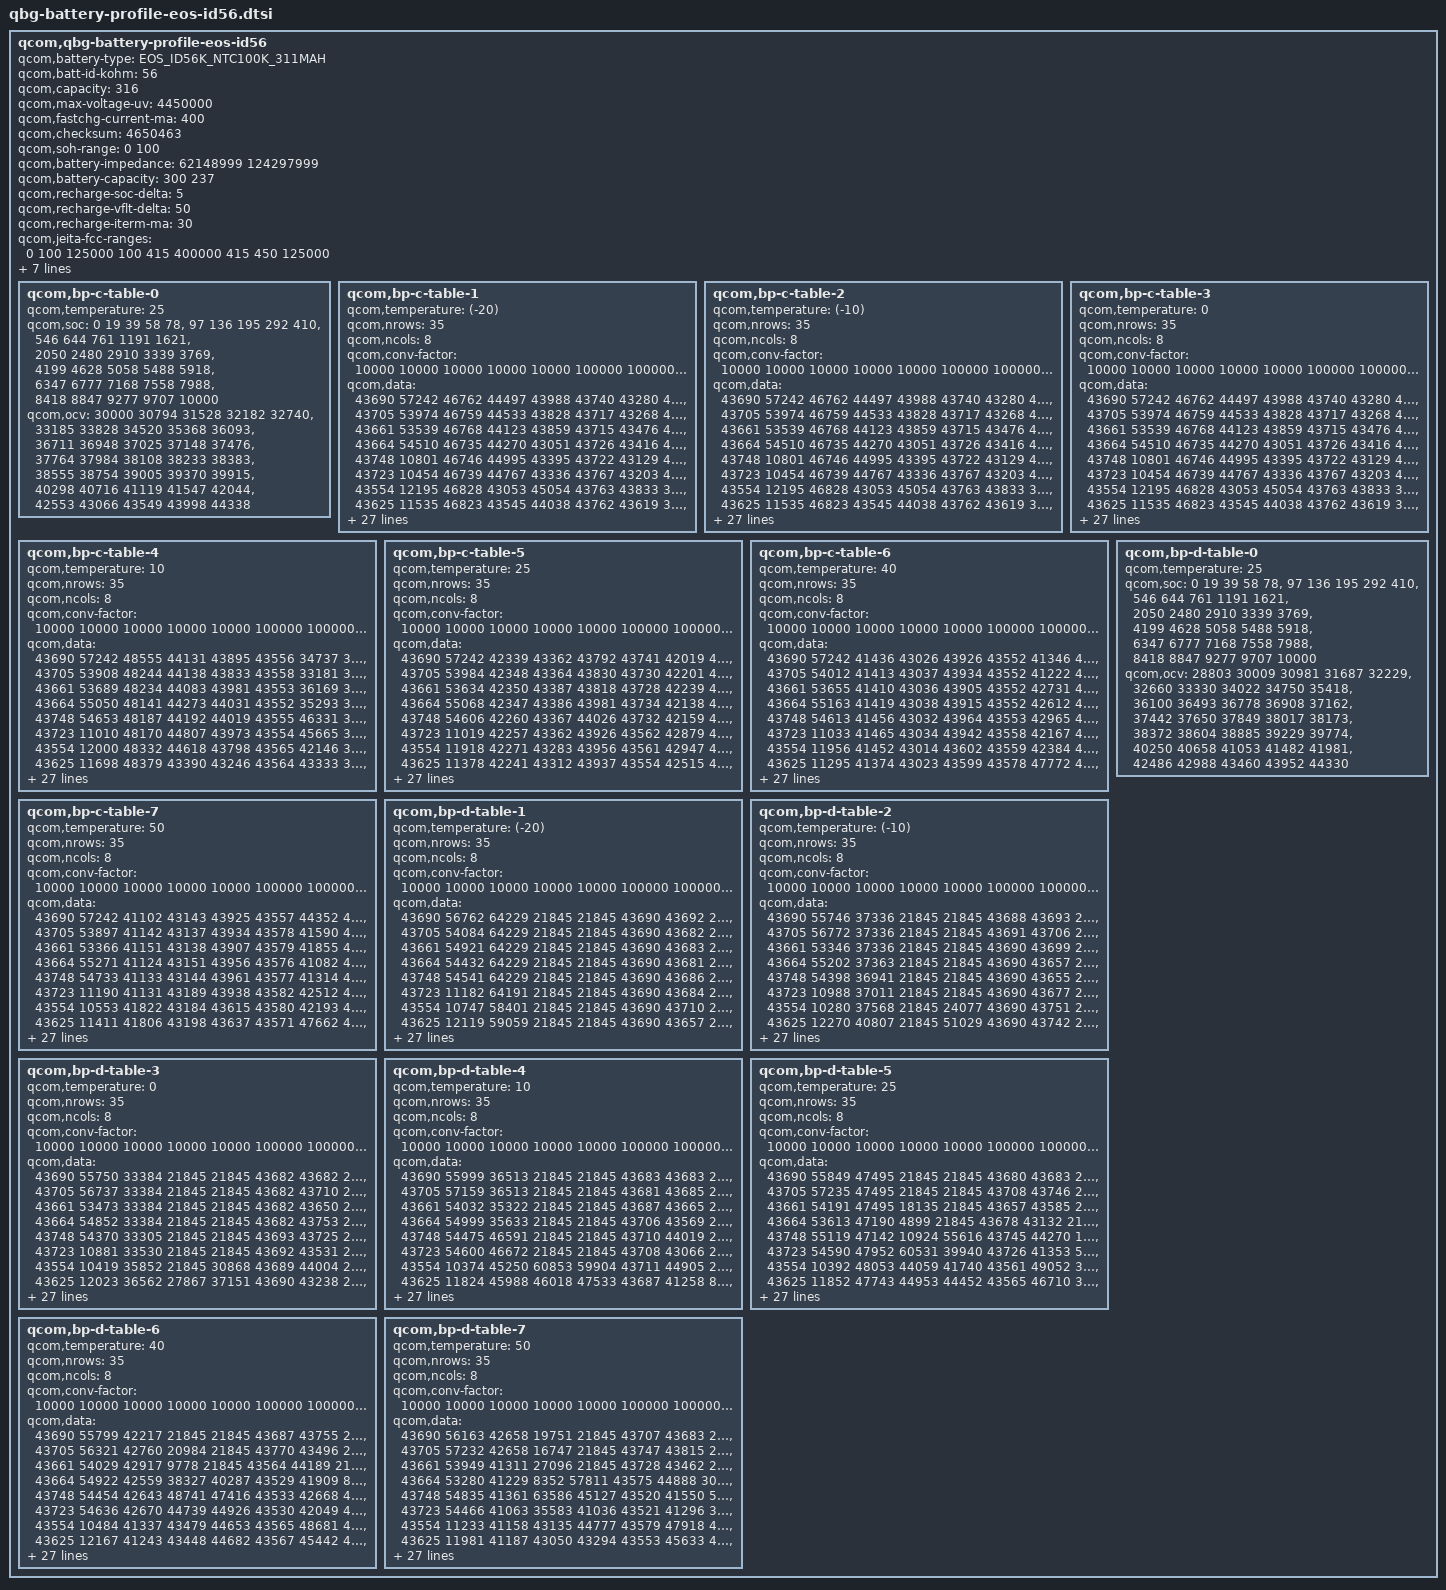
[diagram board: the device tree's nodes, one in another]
// SPDX-License-Identifier: GPL-2.0

/*QBG Profiling Rev. 2.7*/

qcom,qbg-battery-profile-eos-id56 {
	qcom,battery-type = "EOS_ID56K_NTC100K_311MAH";
	qcom,batt-id-kohm = <56>;
	qcom,capacity = <316>;
	qcom,max-voltage-uv = <4450000>;
	qcom,fastchg-current-ma = <400>;
	qcom,checksum = <4650463>; /*@5, 0.005V, 4% */
	qcom,soh-range = <0 100>;
	/*Nominal_Impedance in 10nohm @ SOC 50% 25C* 0:fresh cell, 1: aged cell*/
	qcom,battery-impedance = <62148999 124297999>;
	/*Nominal_Capacity in mAh. 0: fresh cell, 1:aged cell*/
	qcom,battery-capacity = <300 237>;
	/*SOC delta (in percent) dropped from EOC SOC to enable recharge*/
	qcom,recharge-soc-delta =<5>;
	/*vfloat delta (in mV) dropped from regular vfloat in recharge*/
	qcom,recharge-vflt-delta =<50>;
	/*termination current (in mA) in recharge*/
	qcom,recharge-iterm-ma = <30>;
	qcom,jeita-fcc-ranges = <0  100 125000
				100 415 400000
				415 450 125000>;

	qcom,jeita-fv-ranges = <0   100 4450000
				100 415 4450000
				415 450 4450000>;

	/* COOL = 10 DegC, WARM = 41 DegC */
	qcom,jeita-soft-thresholds = <0x2b8a 0x14de>;
	/* COLD = 0 DegC, HOT = 45 DegC */
	qcom,jeita-hard-thresholds = <0x3257 0x128c>;
	/* COOL = 12 DegC, WARM = 39 DegC*/
	qcom,jeita-soft-hys-thresholds = <0x2a0b 0x161b>;
	qcom,jeita-soft-fcc-ua = <125000 125000>;
	qcom,jeita-soft-fv-uv = <4450000 4450000>;

	qcom,bp-c-table-0 {
		qcom,temperature = <25>;
		qcom,soc = <    0    19    39    58    78>,
			<   97   136   195   292   410>,
			<  546   644   761  1191  1621>,
			< 2050  2480  2910  3339  3769>,
			< 4199  4628  5058  5488  5918>,
			< 6347  6777  7168  7558  7988>,
			< 8418  8847  9277  9707 10000>;
		qcom,ocv = <30000 30794 31528 32182 32740>,
			<33185 33828 34520 35368 36093>,
			<36711 36948 37025 37148 37476>,
			<37764 37984 38108 38233 38383>,
			<38555 38754 39005 39370 39915>,
			<40298 40716 41119 41547 42044>,
			<42553 43066 43549 43998 44338>;
	};
	qcom,bp-c-table-1 {
		qcom,temperature = <(-20)>;
		qcom,nrows = <35>;
		qcom,ncols = <8>;
		qcom,conv-factor = <10000 10000 10000 10000 10000 100000 100000 10000>;
		qcom,data = <43690 57242 46762 44497 43988 43740 43280 40143>,
			<43705 53974 46759 44533 43828 43717 43268 40787>,
			<43661 53539 46768 44123 43859 43715 43476 40736>,
			<43664 54510 46735 44270 43051 43726 43416 40881>,
			<43748 10801 46746 44995 43395 43722 43129 40454>,
			<43723 10454 46739 44767 43336 43767 43203 40682>,
			<43554 12195 46828 43053 45054 43763 43833 39379>,
			<43625 11535 46823 43545 44038 43762 43619 38950>,
			<43918  8266 46751 43569 44041 43721 43628 39684>,
			<43824  9993 45378 43828 44838 43734 43931 39841>,
			<43144  9562 46768 43232 44560 43564 43824 39638>,
			<43054 14949 45423 43741 44237 43734 43618 39611>,
			<43091 15294 45433 43578 44229 43561 43622 34174>,
			<44557 15155 45383 44062 43805 43530 47894 39497>,
			<44287 14427 45345 41775 43111 43734 48015 39317>,
			<41640 16050 45371 41215 43476 43731 47288 39204>,
			<41754 15965 45491 41037 43381 43740 47628 39382>,
			<41460 16326 45135 41449 44676 43742 47806 39223>,
			<42913 16230 45487 41248 44743 43737 42268 39281>,
			<42003 15516 45454 41331 44547 43739 42241 40595>,
			<47821 15387 45175 42722 44620 43738 47727 40565>,
			<47294 15854 45172 42596 44984 43739 48864 40749>,
			<47464 12956 45123 42897 44594 43736 48453 40927>,
			<49114 13076 45448 42886 44693 43716 42418 40738>,
			<48564 12700 45367 43006 44562 43724 41709 39965>,
			<45665 13858 46817 42210 44835 43723 44302 37748>,
			<45267 13497 47026 42485 44829 43767 41661 38461>,
			<46762 13624 46969 42272 44083 43760 44813 38003>,
			<46892  2993 46118 47788 44415 43763 44598 59558>,
			<46494  2165 46512 47641 41832 43763 43341 60636>,
			<35400  3602 46354 48050 42498 43761 43496 57677>,
			<34853  3085 35538 48106 48001 43767 43060 63930>,
			<36503   562 35348 48055 45822 43765 43144 63060>,
			<36673   193 35396 47815 36731 43720 43899 51052>,
			<36282   284 35769 42580 34842 43763 43820 50040>;
	};
	qcom,bp-c-table-2 {
		qcom,temperature = <(-10)>;
		qcom,nrows = <35>;
		qcom,ncols = <8>;
		qcom,conv-factor = <10000 10000 10000 10000 10000 100000 100000 10000>;
		qcom,data = <43690 57242 46762 44497 43988 43740 43280 40143>,
			<43705 53974 46759 44533 43828 43717 43268 40787>,
			<43661 53539 46768 44123 43859 43715 43476 40736>,
			<43664 54510 46735 44270 43051 43726 43416 40881>,
			<43748 10801 46746 44995 43395 43722 43129 40454>,
			<43723 10454 46739 44767 43336 43767 43203 40682>,
			<43554 12195 46828 43053 45054 43763 43833 39379>,
			<43625 11535 46823 43545 44038 43762 43619 38950>,
			<43918  8266 46751 43569 44041 43721 43628 39684>,
			<43824  9993 45378 43828 44838 43734 43931 39841>,
			<43144  9562 46768 43232 44560 43564 43824 39638>,
			<43054 14949 45423 43741 44237 43734 43618 39611>,
			<43091 15294 45433 43578 44229 43561 43622 34174>,
			<44557 15155 45383 44062 43805 43530 47894 39497>,
			<44287 14427 45345 41775 43111 43734 48015 39317>,
			<41640 16050 45371 41215 43476 43731 47288 39204>,
			<41754 15965 45491 41037 43381 43740 47628 39382>,
			<41460 16326 45135 41449 44676 43742 47806 39223>,
			<42913 16230 45487 41248 44743 43737 42268 39281>,
			<42003 15516 45454 41331 44547 43739 42241 40595>,
			<47821 15387 45175 42722 44620 43738 47727 40565>,
			<47294 15854 45172 42596 44984 43739 48864 40749>,
			<47464 12956 45123 42897 44594 43736 48453 40927>,
			<49114 13076 45448 42886 44693 43716 42418 40738>,
			<48564 12700 45367 43006 44562 43724 41709 39965>,
			<45665 13858 46817 42210 44835 43723 44302 37748>,
			<45267 13497 47026 42485 44829 43767 41661 38461>,
			<46762 13624 46969 42272 44083 43760 44813 38003>,
			<46892  2993 46118 47788 44415 43763 44598 59558>,
			<46494  2165 46512 47641 41832 43763 43341 60636>,
			<35400  3602 46354 48050 42498 43761 43496 57677>,
			<34853  3085 35538 48106 48001 43767 43060 63930>,
			<36503   562 35348 48055 45822 43765 43144 63060>,
			<36673   193 35396 47815 36731 43720 43899 51052>,
			<36282   284 35769 42580 34842 43763 43820 50040>;
	};
	qcom,bp-c-table-3 {
		qcom,temperature = <0>;
		qcom,nrows = <35>;
		qcom,ncols = <8>;
		qcom,conv-factor = <10000 10000 10000 10000 10000 100000 100000 10000>;
		qcom,data = <43690 57242 46762 44497 43988 43740 43280 40143>,
			<43705 53974 46759 44533 43828 43717 43268 40787>,
			<43661 53539 46768 44123 43859 43715 43476 40736>,
			<43664 54510 46735 44270 43051 43726 43416 40881>,
			<43748 10801 46746 44995 43395 43722 43129 40454>,
			<43723 10454 46739 44767 43336 43767 43203 40682>,
			<43554 12195 46828 43053 45054 43763 43833 39379>,
			<43625 11535 46823 43545 44038 43762 43619 38950>,
			<43918  8266 46751 43569 44041 43721 43628 39684>,
			<43824  9993 45378 43828 44838 43734 43931 39841>,
			<43144  9562 46768 43232 44560 43564 43824 39638>,
			<43054 14949 45423 43741 44237 43734 43618 39611>,
			<43091 15294 45433 43578 44229 43561 43622 34174>,
			<44557 15155 45383 44062 43805 43530 47894 39497>,
			<44287 14427 45345 41775 43111 43734 48015 39317>,
			<41640 16050 45371 41215 43476 43731 47288 39204>,
			<41754 15965 45491 41037 43381 43740 47628 39382>,
			<41460 16326 45135 41449 44676 43742 47806 39223>,
			<42913 16230 45487 41248 44743 43737 42268 39281>,
			<42003 15516 45454 41331 44547 43739 42241 40595>,
			<47821 15387 45175 42722 44620 43738 47727 40565>,
			<47294 15854 45172 42596 44984 43739 48864 40749>,
			<47464 12956 45123 42897 44594 43736 48453 40927>,
			<49114 13076 45448 42886 44693 43716 42418 40738>,
			<48564 12700 45367 43006 44562 43724 41709 39965>,
			<45665 13858 46817 42210 44835 43723 44302 37748>,
			<45267 13497 47026 42485 44829 43767 41661 38461>,
			<46762 13624 46969 42272 44083 43760 44813 38003>,
			<46892  2993 46118 47788 44415 43763 44598 59558>,
			<46494  2165 46512 47641 41832 43763 43341 60636>,
			<35400  3602 46354 48050 42498 43761 43496 57677>,
			<34853  3085 35538 48106 48001 43767 43060 63930>,
			<36503   562 35348 48055 45822 43765 43144 63060>,
			<36673   193 35396 47815 36731 43720 43899 51052>,
			<36282   284 35769 42580 34842 43763 43820 50040>;
	};
	qcom,bp-c-table-4 {
		qcom,temperature = <10>;
		qcom,nrows = <35>;
		qcom,ncols = <8>;
		qcom,conv-factor = <10000 10000 10000 10000 10000 100000 100000 10000>;
		qcom,data = <43690 57242 48555 44131 43895 43556 34737 36150>,
			<43705 53908 48244 44138 43833 43558 33181 36230>,
			<43661 53689 48234 44083 43981 43553 36169 35869>,
			<43664 55050 48141 44273 44031 43552 35293 36072>,
			<43748 54653 48187 44192 44019 43555 46331 36708>,
			<43723 11010 48170 44807 43973 43554 45665 36854>,
			<43554 12000 48332 44618 43798 43565 42146 36384>,
			<43625 11698 48379 43390 43246 43564 43333 35121>,
			<43918  8388 48329 43248 43311 43732 43201 34938>,
			<43824 10133 48986 43369 43168 43577 44749 35059>,
			<43144  9481 48299 44675 43984 43575 41476 35699>,
			<43054 14887 48968 43467 43189 43530 44815 35824>,
			<43091 14951 48923 43380 43780 43573 41592 35717>,
			<44557 15353 48952 45018 43786 43577 47648 35065>,
			<44287 14346 49045 44428 43066 43728 42351 35137>,
			<41640 14697 49078 44325 43404 43731 42454 36501>,
			<41754 15885 48754 44382 43497 43730 42458 36531>,
			<41460 16313 48671 41604 43460 43741 42375 36491>,
			<42913 16340 48678 41723 43325 43741 42828 36508>,
			<42003 16214 48847 41672 43376 43740 41294 36555>,
			<47821 15418 48882 41681 44778 43743 41458 36370>,
			<47294 15773 48893 41582 44592 43742 42927 36844>,
			<47464 12967 48888 41859 44574 43737 47978 36611>,
			<49114 13153 48773 41858 43488 43736 47741 36535>,
			<48564 12603 48828 41701 43461 43739 44523 35210>,
			<45665 14247 48779 41502 43461 43717 44329 35130>,
			<45267 13375 48867 41922 43306 43713 44302 36397>,
			<46762  2740 48684 41822 43377 43725 44181 36627>,
			<46892  2845 48767 40975 44568 43726 44950 36200>,
			<46494  2361 49087 41345 44887 43721 44702 33017>,
			<35400  3880 48903 41335 44393 43726 43274 34561>,
			<34853  3543 48302 41310 40973 43727 43103 39803>,
			<36503   960 48362 41319 42439 43712 43200 40247>,
			<36673   406 48382 41076 48533 43718 43869 38148>,
			<36282  1734 48308 41916 46482 43715 43837 60636>;
	};
	qcom,bp-c-table-5 {
		qcom,temperature = <25>;
		qcom,nrows = <35>;
		qcom,ncols = <8>;
		qcom,conv-factor = <10000 10000 10000 10000 10000 100000 100000 10000>;
		qcom,data = <43690 57242 42339 43362 43792 43741 42019 45731>,
			<43705 53984 42348 43364 43830 43730 42201 48509>,
			<43661 53634 42350 43387 43818 43728 42239 48396>,
			<43664 55068 42347 43386 43981 43734 42138 48607>,
			<43748 54606 42260 43367 44026 43732 42159 48620>,
			<43723 11019 42257 43362 43926 43562 42879 48562>,
			<43554 11918 42271 43283 43956 43561 42947 48232>,
			<43625 11378 42241 43312 43937 43554 42515 48371>,
			<43918  8322 42436 43500 43928 43557 44361 48971>,
			<43824  9815 42494 43427 44028 43570 44073 48934>,
			<43144  9677 42396 43117 44021 43572 44081 49025>,
			<43054 15102 42420 43121 43940 43571 41064 48745>,
			<43091 14859 42400 43097 43588 43580 42748 48655>,
			<44557 15286 42051 43477 43848 43578 41777 48988>,
			<44287 14542 41999 44720 43047 43554 41939 48244>,
			<41640 14638 42203 44790 43086 43552 41116 48538>,
			<41754 16074 42219 44553 43008 43555 42569 48546>,
			<41460 15990 42122 44573 43056 43564 42745 48245>,
			<42913 16371 42836 44643 43107 43554 41129 48554>,
			<42003 16197 42868 44740 43305 43564 44264 48618>,
			<47821 15409 42861 44796 44703 43733 44915 48397>,
			<47294 15816 42783 44576 44786 43732 44519 45745>,
			<47464 13047 42763 44933 44681 43564 42852 45801>,
			<49114 13152 42815 44856 43393 43578 48713 48498>,
			<48564 12609 42805 44545 43230 43735 44275 48313>,
			<45665 14272 42965 44641 43009 43734 44951 48330>,
			<45267 13734 42964 44866 43864 43530 42422 48204>,
			<46762  2613 42964 44894 43041 43554 41742 48446>,
			<46892  2273 42795 44194 43414 43743 44556 45823>,
			<46494  3734 42789 44133 43264 43740 44765 45885>,
			<35400  3219 42777 44310 44611 43736 43359 46728>,
			<34853   656 42822 44408 44099 43743 43401 46302>,
			<36503   183 42161 44386 41746 43732 43111 35792>,
			<36673   372 42819 44459 47764 43553 43152 35916>,
			<36282  1944 42901 44602 41313 43729 43859 46396>;
	};
	qcom,bp-c-table-6 {
		qcom,temperature = <40>;
		qcom,nrows = <35>;
		qcom,ncols = <8>;
		qcom,conv-factor = <10000 10000 10000 10000 10000 100000 100000 10000>;
		qcom,data = <43690 57242 41436 43026 43926 43552 41346 47677>,
			<43705 54012 41413 43037 43934 43552 41222 47828>,
			<43661 53655 41410 43036 43905 43552 42731 47823>,
			<43664 55163 41419 43038 43915 43552 42612 47847>,
			<43748 54613 41456 43032 43964 43553 42965 47775>,
			<43723 11033 41465 43034 43942 43558 42167 47799>,
			<43554 11956 41452 43014 43602 43559 42384 42328>,
			<43625 11295 41374 43023 43599 43578 47772 42262>,
			<43918  9048 41393 43070 43632 43581 47809 42449>,
			<43824  9751 41379 43054 43646 43572 47793 42477>,
			<43144  9609 41043 43155 43615 43546 41455 42071>,
			<43054 14987 41050 43875 43584 43548 40961 42200>,
			<43091 15067 41027 43880 43645 43551 42523 42239>,
			<44557 14967 41078 43160 43866 43524 44185 42318>,
			<44287 14519 41065 43248 43208 43522 44910 47835>,
			<41640 14750 40985 43061 43229 43533 44394 47645>,
			<41754 16036 40968 43025 43147 43531 41307 47837>,
			<41460 15873 41018 43046 43870 43574 41550 47800>,
			<42913 16272 41175 43077 43868 43581 41626 47816>,
			<42003 16202 41165 43053 43132 43529 44791 47730>,
			<47821 15414 41214 43148 43388 43529 43301 48098>,
			<47294 15832 41199 43166 44717 43569 44754 47886>,
			<47464 13009 41107 43112 43374 43568 41946 47898>,
			<49114 13136 41114 43430 43060 43574 42892 48040>,
			<48564 12624 41094 43056 43883 43583 44167 42300>,
			<45665 14295 41090 43112 43894 43576 45039 42312>,
			<45267 13705 41097 43432 43150 43553 44587 47837>,
			<46762  2664 41099 43501 43219 43567 43355 48052>,
			<46892  2271 41096 43269 43029 43562 43350 47987>,
			<46494  3789 41090 44701 43073 43732 44775 47156>,
			<35400  3276 41112 44644 43413 43562 44744 47370>,
			<34853   753 41105 44998 44775 43561 44686 49116>,
			<36503   156 41196 45055 44203 43579 43297 48552>,
			<36673   337 41096 44651 41889 43529 43124 45954>,
			<36282  1997 41915 43015 44372 43579 43876 48734>;
	};
	qcom,bp-c-table-7 {
		qcom,temperature = <50>;
		qcom,nrows = <35>;
		qcom,ncols = <8>;
		qcom,conv-factor = <10000 10000 10000 10000 10000 100000 100000 10000>;
		qcom,data = <43690 57242 41102 43143 43925 43557 44352 41987>,
			<43705 53897 41142 43137 43934 43578 41590 42021>,
			<43661 53366 41151 43138 43907 43579 41855 42207>,
			<43664 55271 41124 43151 43956 43576 41082 42230>,
			<43748 54733 41133 43144 43961 43577 41314 42217>,
			<43723 11190 41131 43189 43938 43582 42512 42113>,
			<43554 10553 41822 43184 43615 43580 42193 42837>,
			<43625 11411 41806 43198 43637 43571 47662 42848>,
			<43918  9002 41850 43194 43619 43575 47319 42815>,
			<43824  9978 41832 43172 43540 43529 47479 42948>,
			<43144  9245 41756 43862 43536 43545 47358 42900>,
			<43054  9597 41755 43972 43624 43646 42502 42551>,
			<43091 15006 41734 44002 43627 43643 42741 42718>,
			<44557 14896 41743 43882 43874 43630 44933 42147>,
			<44287 15231 41778 43897 43168 43630 44928 42235>,
			<41640 14405 41764 43177 43188 43624 44116 42022>,
			<41754 14691 41768 43841 43144 43540 41564 42181>,
			<41460 15917 41951 43884 43777 43549 44391 42873>,
			<42913 16265 41923 43151 43839 43535 44381 42164>,
			<42003 16231 41968 43254 43864 43547 44925 42010>,
			<47821 15417 41953 43826 43512 43631 43412 42378>,
			<47294 15838 41877 43983 43369 43543 43460 42433>,
			<47464 12845 41884 43902 43305 43547 44340 42434>,
			<49114 12453 41860 43199 43256 43547 41118 41994>,
			<48564 12625 41859 43899 43991 43546 44877 42971>,
			<45665 14123 41871 43853 43786 43522 44649 42780>,
			<45267 13703 41867 43191 43847 43573 44714 42220>,
			<46762  2657 41908 43043 43198 43583 44785 42063>,
			<46892  2088 41908 43104 43252 43557 44727 42452>,
			<46494  3804 41866 43400 43071 43555 44700 47797>,
			<35400  3290 41870 43292 43106 43564 44575 47705>,
			<34853   712 41868 44681 43456 43555 44581 47285>,
			<36503   156 41865 44773 44607 43530 44788 47614>,
			<36673  1705 41899 43311 44206 43523 43504 47377>,
			<36282  2003 44306 43214 44035 43523 43256 47948>;
	};
	qcom,bp-d-table-0 {
		qcom,temperature = <25>;
		qcom,soc = <    0    19    39    58    78>,
			<   97   136   195   292   410>,
			<  546   644   761  1191  1621>,
			< 2050  2480  2910  3339  3769>,
			< 4199  4628  5058  5488  5918>,
			< 6347  6777  7168  7558  7988>,
			< 8418  8847  9277  9707 10000>;
		qcom,ocv = <28803 30009 30981 31687 32229>,
			<32660 33330 34022 34750 35418>,
			<36100 36493 36778 36908 37162>,
			<37442 37650 37849 38017 38173>,
			<38372 38604 38885 39229 39774>,
			<40250 40658 41053 41482 41981>,
			<42486 42988 43460 43952 44330>;
	};
	qcom,bp-d-table-1 {
		qcom,temperature = <(-20)>;
		qcom,nrows = <35>;
		qcom,ncols = <8>;
		qcom,conv-factor = <10000 10000 10000 10000 10000 100000 100000 10000>;
		qcom,data = <43690 56762 64229 21845 21845 43690 43692 21845>,
			<43705 54084 64229 21845 21845 43690 43682 21845>,
			<43661 54921 64229 21845 21845 43690 43683 21845>,
			<43664 54432 64229 21845 21845 43690 43681 21845>,
			<43748 54541 64229 21845 21845 43690 43686 21845>,
			<43723 11182 64191 21845 21845 43690 43684 21845>,
			<43554 10747 58401 21845 21845 43690 43710 21845>,
			<43625 12119 59059 21845 21845 43690 43657 21845>,
			<43918  9095 57690 21845  1011 43690 43757 21845>,
			<43824  8501 61418 21845 52133 43690 43567 21845>,
			<43144 10224 59889 21845 38468 43690 43961 21845>,
			<43054  9407 60215 21845 34098 43690 43993 21845>,
			<43091  9228 60216 21845 36733 43690 43791 21845>,
			<44557 14978 38905  6142 35113 43691 43124 21845>,
			<44287 15270 36930 10289 35128 43691 43076 21845>,
			<41640 15112 37409 62638 46166 43688 43114 21845>,
			<41754 14571 40937 61404 45758 43688 43403 21845>,
			<41460 14411 40576 40728 47195 43689 43297 20013>,
			<42913 14635 39149 33026 42396 43694 43338 28006>,
			<42003 16002 39477 36562 42711 43695 44680  6398>,
			<47821 15946 34060 46180 40969 43693 44780  3021>,
			<47294 16135 33878 45256 41950 43682 44739 14694>,
			<47464 15392 34731 48215 41583 43680 44792  8914>,
			<49114 15658 34420 49126 44291 43686 44639 54542>,
			<48564 12861 33057 47419 44038 43684 44885 53927>,
			<45665 13149 32818 47546 44901 43706 41541 56100>,
			<45267 12592 32821 47203 44869 43707 41020 56030>,
			<46762 14111 32879 47314 44461 43651 42285 56117>,
			<46892  2766 32789 47282 41533 43742 46668 56931>,
			<46494  2214 32777 47967 41857 43713 47841 57064>,
			<35400  2376 32964 47177 41706 43739 42375 55616>,
			<34853  3253 32790 47425 41601 43712 42283 56997>,
			<36503   753 32847 47390 44394 43760 42908 55801>,
			<36673    85 32880 47975 44226 43756 44988 55811>,
			<36282  2038 33020 42344 44919 43676 43819 50681>;
	};
	qcom,bp-d-table-2 {
		qcom,temperature = <(-10)>;
		qcom,nrows = <35>;
		qcom,ncols = <8>;
		qcom,conv-factor = <10000 10000 10000 10000 10000 100000 100000 10000>;
		qcom,data = <43690 55746 37336 21845 21845 43688 43693 21845>,
			<43705 56772 37336 21845 21845 43691 43706 21845>,
			<43661 53346 37336 21845 21845 43690 43699 21845>,
			<43664 55202 37363 21845 21845 43690 43657 21845>,
			<43748 54398 36941 21845 21845 43690 43655 21845>,
			<43723 10988 37011 21845 21845 43690 43677 21845>,
			<43554 10280 37568 21845 24077 43690 43751 21845>,
			<43625 12270 40807 21845 51029 43690 43742 21845>,
			<43918  8831 39412 21845 34431 43690 43595 21845>,
			<43824  8565 39439 30205 48573 43690 43790 21845>,
			<43144  9357 34763 50774 47815 43691 43084 21845>,
			<43054  9642 34354 58333 42771 43691 43289 21845>,
			<43091  9516 32819 39235 41053 43688 44761 18450>,
			<44557 14871 36143 35742 41049 43694 44955  3135>,
			<44287 15147 36446 45441 41050 43693 44633  8858>,
			<41640 14500 35211 48657 41529 43705 45043 55524>,
			<41754 14368 34953 42309 44820 43770 44147 51309>,
			<41460 14754 35678 42144 44756 43761 44530 61481>,
			<42913 14650 34998 42585 43291 43722 41635 65480>,
			<42003 16015 34986 41297 43494 43727 41608 64257>,
			<47821 15999 35663 41453 43444 43715 41610 58463>,
			<47294 16147 34954 41394 43433 43716 41163 59349>,
			<47464 15453 35702 41227 43094 43743 47228 59276>,
			<49114 13011 35653 41298 43368 43729 48222 59138>,
			<48564 13143 35708 42627 44791 43732 48840 58542>,
			<45665 12592 34991 42506 44667 43563 48727 58564>,
			<45267 14100 34977 42940 44287 43563 48808 58729>,
			<46762 13630 35668 42957 44429 43732 42484 64242>,
			<46892  2629 34988 42852 44247 43731 41379 58656>,
			<46494  2457 35585 42372 44233 43742 42324 64057>,
			<35400  3984 35702 42450 44059 43719 42231 64436>,
			<34853  3485 35702 42297 44048 43712 42606 64452>,
			<36503   950 35658 42479 44184 43727 41062 64070>,
			<36673   499 35676 42127 44591 43767 41657 58434>,
			<36282  2045 34979 42805 43377 43773 44206 59259>;
	};
	qcom,bp-d-table-3 {
		qcom,temperature = <0>;
		qcom,nrows = <35>;
		qcom,ncols = <8>;
		qcom,conv-factor = <10000 10000 10000 10000 10000 100000 100000 10000>;
		qcom,data = <43690 55750 33384 21845 21845 43682 43682 21845>,
			<43705 56737 33384 21845 21845 43682 43710 21845>,
			<43661 53473 33384 21845 21845 43682 43650 21845>,
			<43664 54852 33384 21845 21845 43682 43753 21845>,
			<43748 54370 33305 21845 21845 43693 43725 21845>,
			<43723 10881 33530 21845 21845 43692 43531 21845>,
			<43554 10419 35852 21845 30868 43689 44004 21845>,
			<43625 12023 36562 27867 37151 43690 43238 21845>,
			<43918 11522 34934 62594 47493 43691 43496 21845>,
			<43824  8268 35729 33182 41479 43691 44723 25211>,
			<43144 10093 46395 48380 44810 43689 44824  8514>,
			<43054  9658 46170 48006 44985 43695 44517 57185>,
			<43091  9472 46255 42172 44773 43693 41684 53007>,
			<44557 14893 46706 41056 43468 43709 41906 64315>,
			<44287 15330 45358 41852 43425 43762 41954 58142>,
			<41640 14523 45478 41940 43056 43727 42369 59485>,
			<41754 14766 45558 41942 43127 43739 46704 38269>,
			<41460 14635 45501 41882 43032 43743 45269 38455>,
			<42913 14670 45448 41478 43211 43741 47609 37657>,
			<42003 16069 45457 41507 43245 43731 47955 40281>,
			<47821 16379 45442 41477 43202 43735 48324 40392>,
			<47294 15582 45495 41596 43430 43562 45611 40418>,
			<47464 15667 45440 41562 43307 43563 47597 40372>,
			<49114 12882 45536 41963 44718 43566 48082 40393>,
			<48564 12484 45527 41739 44788 43561 41986 40209>,
			<45665 14065 45510 41183 45046 43560 47776 37805>,
			<45267 13459 45466 40984 44189 43732 42940 37826>,
			<46762 13681 45478 41051 44263 43730 41959 37839>,
			<46892  2836 45491 42732 44874 43737 42529 36996>,
			<46494  2305 45476 42723 44176 43718 41149 37080>,
			<35400  3852 45136 42695 44269 43715 41912 36932>,
			<34853  3336 45122 42509 44163 43715 41860 37252>,
			<36503   982 45122 42534 44841 43725 41952 36964>,
			<36673   293 45479 41333 43345 43721 41958 37864>,
			<36282  2040 45443 41466 43446 43723 41876 37594>;
	};
	qcom,bp-d-table-4 {
		qcom,temperature = <10>;
		qcom,nrows = <35>;
		qcom,ncols = <8>;
		qcom,conv-factor = <10000 10000 10000 10000 10000 100000 100000 10000>;
		qcom,data = <43690 55999 36513 21845 21845 43683 43683 21845>,
			<43705 57159 36513 21845 21845 43681 43685 21845>,
			<43661 54032 35322 21845 21845 43687 43665 21845>,
			<43664 54999 35633 21845 21845 43706 43569 21845>,
			<43748 54475 46591 21845 21845 43710 44019 21845>,
			<43723 54600 46672 21845 21845 43708 43066 21845>,
			<43554 10374 45250 60853 59904 43711 44905 20396>,
			<43625 11824 45988 46018 47533 43687 41258  8944>,
			<43918 11576 45797 42085 44098 43706 47259 51630>,
			<43824  8408 48400 41512 43433 43656 47885 57501>,
			<43144 10133 48556 44065 43220 43665 42749 38079>,
			<43054  9327 48550 44220 43008 43768 41020 37755>,
			<43091  9485 48201 44895 43025 43742 41055 40373>,
			<44557 14996 48143 44834 43903 43737 41360 34071>,
			<44287 15353 48957 44247 43256 43738 42407 34689>,
			<41640 14554 48935 44254 43403 43731 42433 32973>,
			<41754 14769 49144 44278 43447 43562 42088 33434>,
			<41460 14651 49028 44263 43024 43566 42066 36076>,
			<42913 16008 49024 44275 43064 43565 47891 36835>,
			<42003 15939 49050 44229 43014 43554 48809 36475>,
			<47821 16151 49128 44238 43126 43565 47830 36598>,
			<47294 15366 49038 44253 43096 43554 42170 36519>,
			<47464 15715 48734 44038 43455 43565 42516 35136>,
			<49114 13238 48735 44110 43511 43567 41470 36528>,
			<48564 12314 49072 44538 43294 43561 41421 36376>,
			<45665 13881 48733 44387 44584 43560 41261 36628>,
			<45267 13373 48749 41473 44568 43561 42590 35844>,
			<46762  2802 48667 41875 44604 43560 42838 36279>,
			<46892  2218 48650 41596 44989 43742 41478 36323>,
			<46494  2395 48665 41558 44629 43743 44299 36152>,
			<35400  3908 48750 41961 44562 43743 44395 36175>,
			<34853  3395 48750 41925 44591 43743 41720 33425>,
			<36503   784 48762 41958 44683 43737 41490 33459>,
			<36673   263 48722 41522 43513 43717 41558 36243>,
			<36282  2018 49079 41653 43129 43718 41503 36063>;
	};
	qcom,bp-d-table-5 {
		qcom,temperature = <25>;
		qcom,nrows = <35>;
		qcom,ncols = <8>;
		qcom,conv-factor = <10000 10000 10000 10000 10000 100000 100000 10000>;
		qcom,data = <43690 55849 47495 21845 21845 43680 43683 21845>,
			<43705 57235 47495 21845 21845 43708 43746 21845>,
			<43661 54191 47495 18135 21845 43657 43585 21845>,
			<43664 53613 47190  4899 21845 43678 43132 21845>,
			<43748 55119 47142 10924 55616 43745 44270 19122>,
			<43723 54590 47952 60531 39940 43726 41353 56788>,
			<43554 10392 48053 44059 41740 43561 49052 36336>,
			<43625 11852 47743 44953 44452 43565 46710 35048>,
			<43918 11540 47719 44649 44666 43564 35534 46591>,
			<43824  8432 47618 44594 43063 43552 46322 46713>,
			<43144 10158 47674 44692 43777 43559 48143 45125>,
			<43054  9255 47813 43351 43791 43553 41331 45219>,
			<43091  9472 47847 44786 43840 43581 41355 45255>,
			<44557 14982 47797 43322 43928 43560 43001 48470>,
			<44287 15232 42288 43361 43855 43563 40960 45738>,
			<41640 14568 42427 43385 43222 43582 41807 48442>,
			<41754 14776 42057 43328 43104 43580 40977 48595>,
			<41460 14707 42005 44732 43449 43573 42911 48432>,
			<42913 15915 42045 44712 43419 43530 42738 48595>,
			<42003 16311 42206 43361 43407 43570 41870 48249>,
			<47821 16206 42232 43336 43031 43568 41896 48371>,
			<47294 15462 42112 43333 43206 43570 41906 48972>,
			<47464 15695 42148 44719 43246 43583 41835 48924>,
			<49114 13207 42832 44725 43217 43559 41824 48962>,
			<48564 12788 42817 44990 43469 43532 48253 48484>,
			<45665 14224 42853 45037 43359 43535 49074 45774>,
			<45267 13432 42780 44965 44717 43579 41328 45792>,
			<46762  2807 42778 44622 43348 43555 41621 45743>,
			<46892  2208 42782 44666 43377 43554 44064 48497>,
			<46494  2391 42772 44991 43509 43559 44039 48407>,
			<35400  3932 42852 44999 43033 43578 44390 48440>,
			<34853  3398 42817 45015 43262 43559 41545 48589>,
			<36503   878 42144 45029 43141 43558 41737 48512>,
			<36673   282 42126 44659 43171 43556 41463 48251>,
			<36282  1920 42117 44757 43866 43582 42531 48165>;
	};
	qcom,bp-d-table-6 {
		qcom,temperature = <40>;
		qcom,nrows = <35>;
		qcom,ncols = <8>;
		qcom,conv-factor = <10000 10000 10000 10000 10000 100000 100000 10000>;
		qcom,data = <43690 55799 42217 21845 21845 43687 43755 21845>,
			<43705 56321 42760 20984 21845 43770 43496 21845>,
			<43661 54029 42917  9778 21845 43564 44189 21845>,
			<43664 54922 42559 38327 40287 43529 41909  8715>,
			<43748 54454 42643 48741 47416 43533 42668 40337>,
			<43723 54636 42670 44739 44926 43530 42049 48456>,
			<43554 10484 41337 43479 44653 43565 48681 49105>,
			<43625 12167 41243 43448 44682 43567 45442 48778>,
			<43918  8955 41255 43099 43373 43555 35533 47559>,
			<43824  8215 41434 43097 43209 43559 35604 47989>,
			<43144 10122 41456 43104 43965 43582 46721 47764>,
			<43054  9227 41445 43128 43605 43580 42053 47752>,
			<43091  9474 41441 43492 43920 43570 42581 47691>,
			<44557 15032 41372 43212 43541 43580 47708 42485>,
			<44287 15269 41379 43230 43984 43535 40970 42311>,
			<41640 14518 41033 43034 43798 43544 40986 47850>,
			<41754 14783 41083 43068 43205 43546 41809 47721>,
			<41460 14663 40981 43060 43085 43629 41574 48016>,
			<42913 15923 40961 43122 43030 43609 41598 48026>,
			<42003 16277 41021 43425 43137 43604 41199 47718>,
			<47821 15520 41004 43450 43894 43592 41257 47811>,
			<47294 15451 41181 43129 43782 43624 41363 42307>,
			<47464 15701 41155 43066 43813 43526 41118 42451>,
			<49114 13250 41207 43023 43891 43522 41308 42362>,
			<48564 12766 41210 43084 43490 43523 42119 47906>,
			<45665 14223 41197 43028 43373 43531 40996 47974>,
			<45267 13328 41195 43060 43371 43574 44037 47884>,
			<46762  2814 41109 43114 43487 43573 44183 47919>,
			<46892  2900 41194 43419 43037 43527 44113 48109>,
			<46494  2421 41193 43295 43793 43548 41971 47694>,
			<35400  3960 41189 43288 44000 43575 41435 47663>,
			<34853  3436 41212 43470 43923 43556 41237 47796>,
			<36503   821 41163 43424 43932 43557 42720 42342>,
			<36673   290 41170 43119 43925 43529 42792 42301>,
			<36282  1618 40994 43023 44015 43543 42132 42275>;
	};
	qcom,bp-d-table-7 {
		qcom,temperature = <50>;
		qcom,nrows = <35>;
		qcom,ncols = <8>;
		qcom,conv-factor = <10000 10000 10000 10000 10000 100000 100000 10000>;
		qcom,data = <43690 56163 42658 19751 21845 43707 43683 21845>,
			<43705 57232 42658 16747 21845 43747 43815 21845>,
			<43661 53949 41311 27096 21845 43728 43462 21845>,
			<43664 53280 41229  8352 57811 43575 44888  3098>,
			<43748 54835 41361 63586 45127 43520 41550 57846>,
			<43723 54466 41063 35583 41036 43521 41296 35269>,
			<43554 11233 41158 43135 44777 43579 47918 47209>,
			<43625 11981 41187 43050 43294 43553 45633 47887>,
			<43918 11639 41094 43256 43315 43579 46393 48005>,
			<43824  8399 41124 43240 43053 43580 34904 42354>,
			<43144  9835 41814 43243 43921 43569 34870 42180>,
			<43054  9374 41816 43153 43635 43572 48180 42844>,
			<43091  9667 41818 43027 43966 43570 42832 42013>,
			<44557  9548 41802 43902 43533 43534 47804 42989>,
			<44287 14968 41838 43176 43915 43626 42919 42860>,
			<41640 15183 41755 43148 43998 43628 41027 42113>,
			<41754 14448 41740 43182 43869 43622 41967 42182>,
			<41460 14692 41782 43252 43167 43959 41802 42417>,
			<42913 15925 41786 43012 43158 43932 41018 42442>,
			<42003 16383 41768 43011 43142 43604 41107 42388>,
			<47821 15539 41948 43055 43903 43599 41809 42012>,
			<47294 15443 41921 43203 44020 43623 41252 42174>,
			<47464 12972 41931 43143 43916 43630 42852 42813>,
			<49114 13269 41981 43141 43828 43541 42062 42144>,
			<48564 12750 41953 43175 43445 43538 41405 42446>,
			<45665 14258 41966 43847 43302 43551 44431 42265>,
			<45267 13330 41877 43871 43474 43548 44902 42255>,
			<46762  2785 41879 43208 43105 43630 44070 42463>,
			<46892  2883 41876 43458 44005 43944 42751 42430>,
			<46494  2425 41963 43419 43916 43544 41440 42003>,
			<35400  3939 41967 43076 43611 43583 42962 42215>,
			<34853  3345 41953 43065 43586 43580 42839 42828>,
			<36503   827 41982 43155 43609 43531 42974 42803>,
			<36673   464 41931 43845 43952 43551 41462 42945>,
			<36282  1607 41920 43887 43910 43625 41201 42958>;
	};
};
